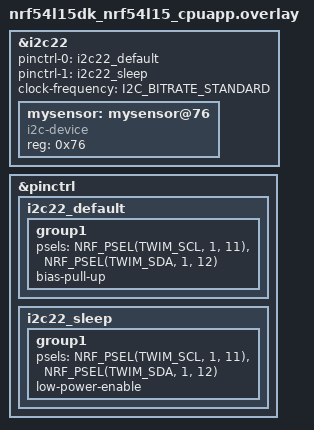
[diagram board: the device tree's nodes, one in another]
// To get started, press Ctrl+Space to bring up the completion menu and view the available nodes.

// You can also use the buttons in the sidebar to perform actions on nodes.
// Actions currently available include:

// * Enabling / disabling the node
// * Adding the bus to a bus
// * Removing the node
// * Connecting ADC channels

// For more help, browse the DeviceTree documentation at https://docs.zephyrproject.org/latest/guides/dts/index.html
// You can also visit the nRF DeviceTree extension documentation at https://docs.nordicsemi.com/bundle/nrf-connect-vscode/page/guides/ncs_configure_app.html#devicetree-support-in-the-extension
&i2c22 {
    status = "okay";
    pinctrl-0 = <&i2c22_default>;
	  pinctrl-1 = <&i2c22_sleep>;
    pinctrl-names = "default", "sleep";
    mysensor: mysensor@76{
        compatible = "i2c-device";
        status = "okay";
        reg = < 0x76 >;
    };

    clock-frequency = <I2C_BITRATE_STANDARD>;
};

&pinctrl {
	/omit-if-no-ref/ i2c22_default: i2c22_default {
		group1  {
			psels = <NRF_PSEL(TWIM_SCL, 1, 11)>,
					<NRF_PSEL(TWIM_SDA, 1, 12)>;
			bias-pull-up;	
		};
	};

	/omit-if-no-ref/ i2c22_sleep: i2c22_sleep {
		group1  {
			psels = <NRF_PSEL(TWIM_SCL, 1, 11)>,
					<NRF_PSEL(TWIM_SDA, 1, 12)>;
			low-power-enable;
		};
	};
};
